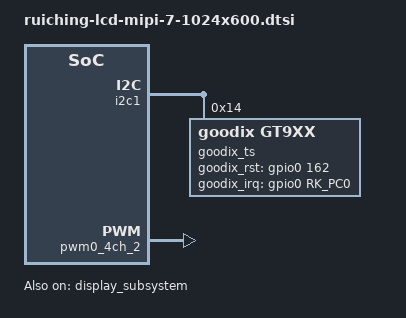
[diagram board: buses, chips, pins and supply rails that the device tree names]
&i2c1 {
    status = "okay";
    pinctrl-names = "default";

    goodix_ts: goodix_ts@14 {
        status = "okay";
        compatible = "goodix,gt9xx";
        reg = <0x14>;
        gtp_resolution_x = <1024>;
        gtp_resolution_y = <600>;
        gtp_int_tarigger = <1>;
        gtp_change_x2y = <0>;
        gtp_overturn_x = <1>;
        gtp_overturn_y = <1>;
        gtp_send_cfg = <0>;
        gtp_touch_wakeup = <1>;

        goodix_rst_gpio = <&gpio0 162 GPIO_ACTIVE_HIGH>;
        goodix_irq_gpio = <&gpio0 RK_PC0 IRQ_TYPE_EDGE_FALLING>;
    };
};

&backlight {
    pwms = <&pwm0_4ch_2 0 500000 0>;
};

&pwm0_4ch_2 {
    status = "okay";
};

&display_subsystem {
    status = "okay";
};

&dsi_panel {
    status = "okay";

    prepare-delay-ms = <20>;
    reset-delay-ms = <80>;
    init-delay-ms = <240>;
    
    panel-init-sequence = [
        15 00 02 b2 10
        15 00 02 80 ac
        15 00 02 81 b8
        15 00 02 82 09
        15 00 02 83 78
        15 00 02 84 7f
        15 00 02 85 bb
        15 00 02 86 70
    ];
};

&dsi_timing0 {
    clock-frequency = <51200000>;
    hactive = <1024>;
    vactive = <600>;
    hback-porch = <90>;
    hfront-porch = <160>;
    vback-porch = <23>;
    vfront-porch = <12>;
    hsync-len = <70>;
    vsync-len = <10>;
};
